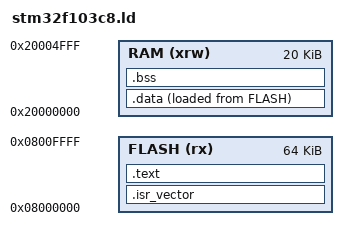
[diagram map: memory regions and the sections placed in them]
/* STM32F103C8: 64 КБ Flash, 20 КБ SRAM. Стек растёт от конца RAM вниз. */
ENTRY(Reset_Handler)

MEMORY
{
    FLASH (rx) : ORIGIN = 0x08000000, LENGTH = 64K
    RAM (xrw)  : ORIGIN = 0x20000000, LENGTH = 20K
}

_estack = ORIGIN(RAM) + LENGTH(RAM);

SECTIONS
{
    .isr_vector :
    {
        KEEP(*(.isr_vector))
    } > FLASH

    .text :
    {
        *(.text*)
        *(.rodata*)
        _etext = .;
    } > FLASH

    _sidata = LOADADDR(.data);

    .data :
    {
        _sdata = .;
        *(.data*)
        _edata = .;
    } > RAM AT > FLASH

    .bss :
    {
        _sbss = .;
        *(.bss*)
        *(COMMON)
        _ebss = .;
    } > RAM
}
